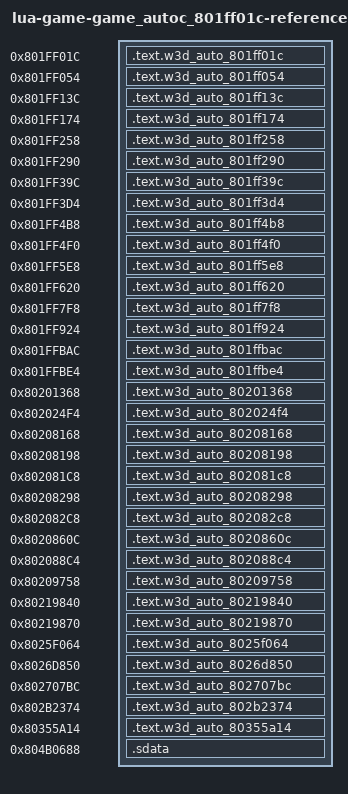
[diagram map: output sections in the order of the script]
/* Generated reference-only placements. All bodies are source-built. */
OUTPUT_FORMAT("elf32-powerpc")
OUTPUT_ARCH(powerpc)
ENTRY(w3d_auto_801ff01c)
_SDA_BASE_ = 0x804b2540;
_SDA2_BASE_ = 0x804c2540;
fn_80178C48 = 0x80178c48;
fn_80178D1C = 0x80178d1c;
fn_80179170 = 0x80179170;
fn_8020C5C0 = 0x8020c5c0;
fn_8020C5C4 = 0x8020c5c4;
fn_80341588 = 0x80341588;
fn_80341884 = 0x80341884;
fn_803426B4 = 0x803426b4;
fn_80342A78 = 0x80342a78;
fn_80343744 = 0x80343744;
SECTIONS {
  .text.w3d_auto_801ff01c 0x801ff01c : { *(.text.w3d_auto_801ff01c) }
  .text.w3d_auto_801ff054 0x801ff054 : { *(.text.w3d_auto_801ff054) }
  .text.w3d_auto_801ff13c 0x801ff13c : { *(.text.w3d_auto_801ff13c) }
  .text.w3d_auto_801ff174 0x801ff174 : { *(.text.w3d_auto_801ff174) }
  .text.w3d_auto_801ff258 0x801ff258 : { *(.text.w3d_auto_801ff258) }
  .text.w3d_auto_801ff290 0x801ff290 : { *(.text.w3d_auto_801ff290) }
  .text.w3d_auto_801ff39c 0x801ff39c : { *(.text.w3d_auto_801ff39c) }
  .text.w3d_auto_801ff3d4 0x801ff3d4 : { *(.text.w3d_auto_801ff3d4) }
  .text.w3d_auto_801ff4b8 0x801ff4b8 : { *(.text.w3d_auto_801ff4b8) }
  .text.w3d_auto_801ff4f0 0x801ff4f0 : { *(.text.w3d_auto_801ff4f0) }
  .text.w3d_auto_801ff5e8 0x801ff5e8 : { *(.text.w3d_auto_801ff5e8) }
  .text.w3d_auto_801ff620 0x801ff620 : { *(.text.w3d_auto_801ff620) }
  .text.w3d_auto_801ff7f8 0x801ff7f8 : { *(.text.w3d_auto_801ff7f8) }
  .text.w3d_auto_801ff924 0x801ff924 : { *(.text.w3d_auto_801ff924) }
  .text.w3d_auto_801ffbac 0x801ffbac : { *(.text.w3d_auto_801ffbac) }
  .text.w3d_auto_801ffbe4 0x801ffbe4 : { *(.text.w3d_auto_801ffbe4) }
  .text.w3d_auto_80201368 0x80201368 : { *(.text.w3d_auto_80201368) }
  .text.w3d_auto_802024f4 0x802024f4 : { *(.text.w3d_auto_802024f4) }
  .text.w3d_auto_80208168 0x80208168 : { *(.text.w3d_auto_80208168) }
  .text.w3d_auto_80208198 0x80208198 : { *(.text.w3d_auto_80208198) }
  .text.w3d_auto_802081c8 0x802081c8 : { *(.text.w3d_auto_802081c8) }
  .text.w3d_auto_80208298 0x80208298 : { *(.text.w3d_auto_80208298) }
  .text.w3d_auto_802082c8 0x802082c8 : { *(.text.w3d_auto_802082c8) }
  .text.w3d_auto_8020860c 0x8020860c : { *(.text.w3d_auto_8020860c) }
  .text.w3d_auto_802088c4 0x802088c4 : { *(.text.w3d_auto_802088c4) }
  .text.w3d_auto_80209758 0x80209758 : { *(.text.w3d_auto_80209758) }
  .text.w3d_auto_80219840 0x80219840 : { *(.text.w3d_auto_80219840) }
  .text.w3d_auto_80219870 0x80219870 : { *(.text.w3d_auto_80219870) }
  .text.w3d_auto_8025f064 0x8025f064 : { *(.text.w3d_auto_8025f064) }
  .text.w3d_auto_8026d850 0x8026d850 : { *(.text.w3d_auto_8026d850) }
  .text.w3d_auto_802707bc 0x802707bc : { *(.text.w3d_auto_802707bc) }
  .text.w3d_auto_802b2374 0x802b2374 : { *(.text.w3d_auto_802b2374) }
  .text.w3d_auto_80355a14 0x80355a14 : { *(.text.w3d_auto_80355a14) }
  .sdata 0x804b0688 (NOLOAD) : {
    . = 0x0; lbl_804B0688 = .;
    . += 1; }
  /DISCARD/ : { *(.text*) *(.rodata*) *(.data*) *(.bss*) *(.sdata*) *(.sbss*) *(.comment) }
}
